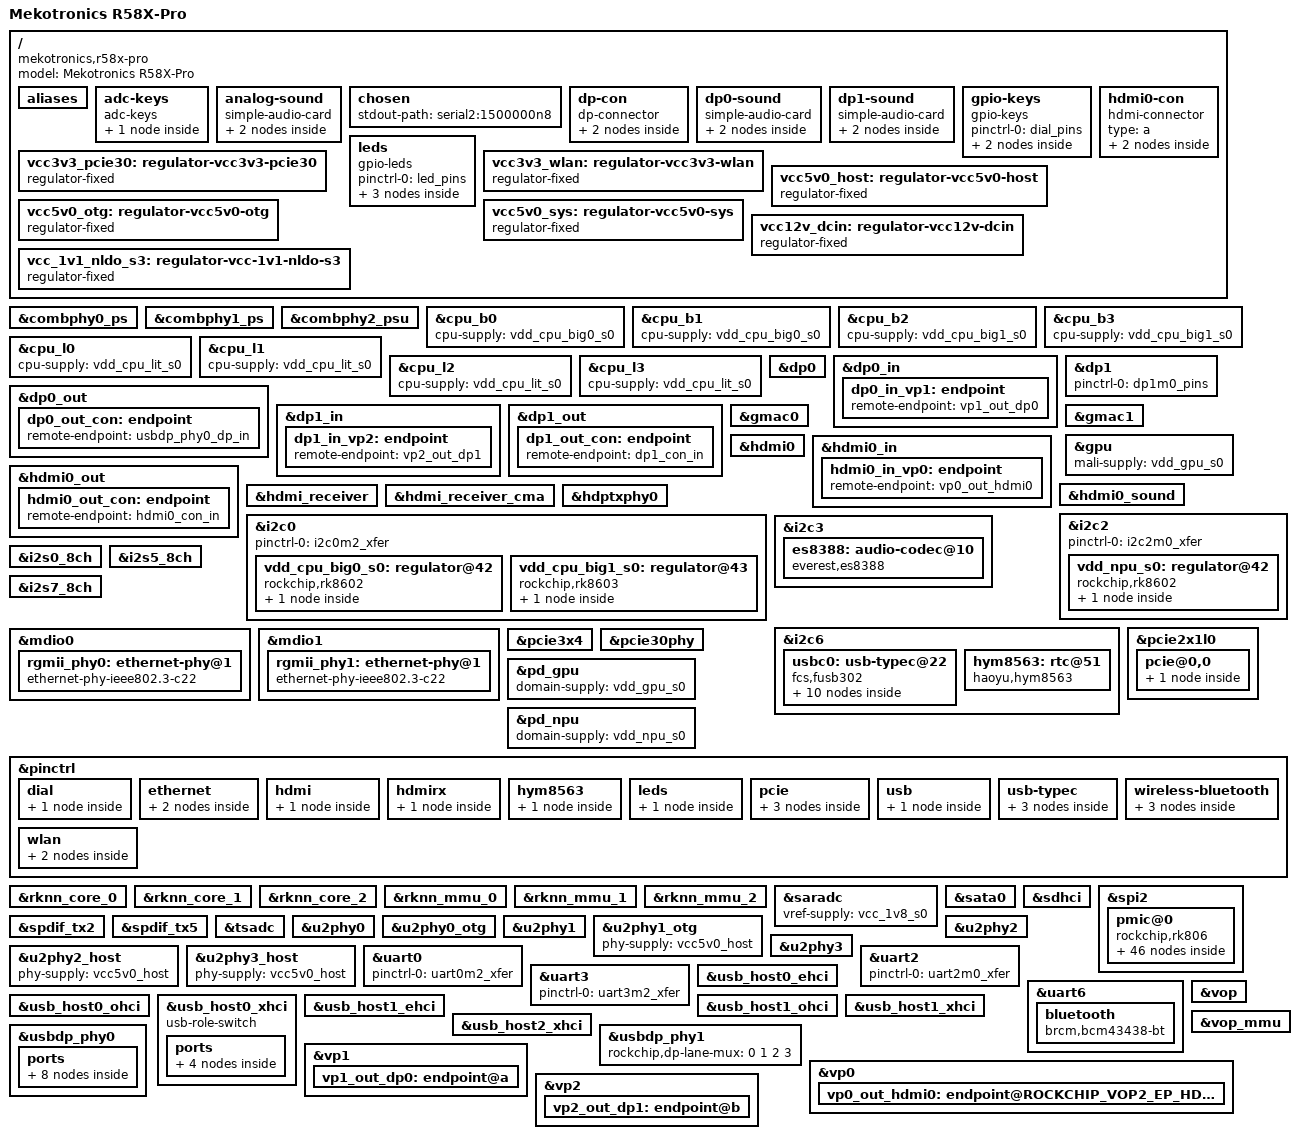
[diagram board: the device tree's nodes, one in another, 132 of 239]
// SPDX-License-Identifier: (GPL-2.0+ OR MIT)
/*
 * Copyright (c) 2026 Ricardo Pardini <ricardo@pardini.net>
 */

/dts-v1/;

#include <dt-bindings/gpio/gpio.h>
#include <dt-bindings/input/input.h>
#include <dt-bindings/leds/common.h>
#include <dt-bindings/pinctrl/rockchip.h>
#include <dt-bindings/soc/rockchip,vop2.h>
#include <dt-bindings/usb/pd.h>
#include "rk3588.dtsi"

/ {
	model = "Mekotronics R58X-Pro";
	compatible = "mekotronics,r58x-pro", "rockchip,rk3588";

	aliases {
		ethernet0 = &gmac0;
		ethernet1 = &gmac1;
		mmc0 = &sdhci;
	};

	adc-keys {
		compatible = "adc-keys";
		io-channels = <&saradc 1>;
		io-channel-names = "buttons";
		keyup-threshold-microvolt = <1800000>;
		poll-interval = <100>;

		button-recovery {
			label = "Recovery";
			linux,code = <KEY_VENDOR>;
			press-threshold-microvolt = <17000>;
		};
	};

	analog-sound {
		compatible = "simple-audio-card";
		simple-audio-card,name = "rockchip-es8388";
		simple-audio-card,bitclock-master = <&daicpu>;
		simple-audio-card,format = "i2s";
		simple-audio-card,frame-master = <&daicpu>;
		simple-audio-card,mclk-fs = <256>;
		simple-audio-card,routing =
			"Headphones", "LOUT1",
			"Headphones", "ROUT1",
			"LINPUT2", "Microphone Jack";
		simple-audio-card,widgets =
			"Microphone", "Microphone Jack",
			"Headphone", "Headphones";

		simple-audio-card,codec {
			sound-dai = <&es8388>;
			system-clock-frequency = <12288000>;
		};

		daicpu: simple-audio-card,cpu {
			sound-dai = <&i2s0_8ch>;
		};
	};

	chosen {
		stdout-path = "serial2:1500000n8";
	};

	dp-con {
		compatible = "dp-connector";
		label = "DP";
		type = "full-size";

		port {
			dp1_con_in: endpoint {
				remote-endpoint = <&dp1_out_con>;
			};
		};
	};

	dp0-sound {
		compatible = "simple-audio-card";
		simple-audio-card,mclk-fs = <512>;
		simple-audio-card,name = "RK3588 DP0";

		simple-audio-card,codec {
			sound-dai = <&dp0 1>;
		};

		simple-audio-card,cpu {
			sound-dai = <&spdif_tx2>;
		};
	};

	dp1-sound {
		compatible = "simple-audio-card";
		simple-audio-card,mclk-fs = <512>;
		simple-audio-card,name = "RK3588 DP1";

		simple-audio-card,codec {
			sound-dai = <&dp1 1>;
		};

		simple-audio-card,cpu {
			sound-dai = <&spdif_tx5>;
		};
	};

	gpio-keys {
		compatible = "gpio-keys";
		pinctrl-names = "default";
		pinctrl-0 = <&dial_pins>;

		key-volume-down {
			gpios = <&gpio3 RK_PC6 GPIO_ACTIVE_HIGH>;
			label = "Volume Down";
			linux,code = <KEY_VOLUMEDOWN>;
		};

		key-volume-up {
			gpios = <&gpio3 RK_PD0 GPIO_ACTIVE_HIGH>;
			label = "Volume Up";
			linux,code = <KEY_VOLUMEUP>;
		};
	};

	hdmi0-con {
		compatible = "hdmi-connector";
		type = "a";

		port {
			hdmi0_con_in: endpoint {
				remote-endpoint = <&hdmi0_out_con>;
			};
		};
	};

	leds {
		compatible = "gpio-leds";
		pinctrl-names = "default";
		pinctrl-0 = <&led_pins>;

		led-0 {
			color = <LED_COLOR_ID_GREEN>;
			function = LED_FUNCTION_LAN;
			gpios = <&gpio3 RK_PC0 GPIO_ACTIVE_HIGH>;
		};

		led-1 {
			color = <LED_COLOR_ID_BLUE>;
			default-state = "on";
			function = LED_FUNCTION_POWER;
			gpios = <&gpio3 RK_PB7 GPIO_ACTIVE_HIGH>;
		};

		led-2 {
			color = <LED_COLOR_ID_GREEN>;
			function = LED_FUNCTION_WLAN;
			gpios = <&gpio3 RK_PC5 GPIO_ACTIVE_HIGH>;
		};
	};

	vcc3v3_pcie30: regulator-vcc3v3-pcie30 {
		compatible = "regulator-fixed";
		enable-active-high;
		gpios = <&gpio1 RK_PC4 GPIO_ACTIVE_HIGH>;
		pinctrl-names = "default";
		pinctrl-0 = <&pcie30x4_pwren>;
		regulator-name = "vcc3v3_pcie30";
		regulator-min-microvolt = <3300000>;
		regulator-max-microvolt = <3300000>;
		startup-delay-us = <10000>;
		vin-supply = <&vcc12v_dcin>;
	};

	vcc3v3_wlan: regulator-vcc3v3-wlan {
		compatible = "regulator-fixed";
		enable-active-high;
		gpios = <&gpio1 RK_PB1 GPIO_ACTIVE_HIGH>;
		pinctrl-names = "default";
		pinctrl-0 = <&wifi_pwren>;
		regulator-name = "vcc3v3_wlan";
		regulator-min-microvolt = <3300000>;
		regulator-max-microvolt = <3300000>;
		vin-supply = <&vcc12v_dcin>;
	};

	vcc5v0_host: regulator-vcc5v0-host {
		compatible = "regulator-fixed";
		enable-active-high;
		gpio = <&gpio4 RK_PB0 GPIO_ACTIVE_HIGH>;
		pinctrl-names = "default";
		pinctrl-0 = <&vcc5v0_host_en>;
		regulator-name = "vcc5v0_host";
		regulator-min-microvolt = <5000000>;
		regulator-max-microvolt = <5000000>;
		vin-supply = <&vcc5v0_sys>;
	};

	vcc5v0_otg: regulator-vcc5v0-otg {
		compatible = "regulator-fixed";
		enable-active-high;
		gpio = <&gpio4 RK_PA7 GPIO_ACTIVE_HIGH>;
		pinctrl-names = "default";
		pinctrl-0 = <&vcc5v0_otg_en>;
		regulator-name = "vcc5v0_otg";
		regulator-min-microvolt = <5000000>;
		regulator-max-microvolt = <5000000>;
		vin-supply = <&vcc5v0_sys>;
	};

	vcc5v0_sys: regulator-vcc5v0-sys {
		compatible = "regulator-fixed";
		regulator-name = "vcc5v0_sys";
		regulator-always-on;
		regulator-boot-on;
		regulator-min-microvolt = <5000000>;
		regulator-max-microvolt = <5000000>;
		vin-supply = <&vcc12v_dcin>;
	};

	vcc12v_dcin: regulator-vcc12v-dcin {
		compatible = "regulator-fixed";
		regulator-name = "vcc12v_dcin";
		regulator-always-on;
		regulator-boot-on;
		regulator-min-microvolt = <12000000>;
		regulator-max-microvolt = <12000000>;
	};

	vcc_1v1_nldo_s3: regulator-vcc-1v1-nldo-s3 {
		compatible = "regulator-fixed";
		regulator-name = "vcc_1v1_nldo_s3";
		regulator-always-on;
		regulator-boot-on;
		regulator-min-microvolt = <1100000>;
		regulator-max-microvolt = <1100000>;
		vin-supply = <&vcc5v0_sys>;
	};
};

&combphy0_ps {
	status = "okay";
};

&combphy1_ps {
	status = "okay";
};

&combphy2_psu {
	status = "okay";
};

&cpu_b0 {
	cpu-supply = <&vdd_cpu_big0_s0>;
};

&cpu_b1 {
	cpu-supply = <&vdd_cpu_big0_s0>;
};

&cpu_b2 {
	cpu-supply = <&vdd_cpu_big1_s0>;
};

&cpu_b3 {
	cpu-supply = <&vdd_cpu_big1_s0>;
};

&cpu_l0 {
	cpu-supply = <&vdd_cpu_lit_s0>;
};

&cpu_l1 {
	cpu-supply = <&vdd_cpu_lit_s0>;
};

&cpu_l2 {
	cpu-supply = <&vdd_cpu_lit_s0>;
};

&cpu_l3 {
	cpu-supply = <&vdd_cpu_lit_s0>;
};

&dp0 {
	#sound-dai-cells = <1>;
	status = "okay";
};

&dp0_in {
	dp0_in_vp1: endpoint {
		remote-endpoint = <&vp1_out_dp0>;
	};
};

&dp0_out {
	dp0_out_con: endpoint {
		remote-endpoint = <&usbdp_phy0_dp_in>;
	};
};

&dp1 {
	pinctrl-names = "default";
	pinctrl-0 = <&dp1m0_pins>;
	#sound-dai-cells = <1>;
	status = "okay";
};

&dp1_in {
	dp1_in_vp2: endpoint {
		remote-endpoint = <&vp2_out_dp1>;
	};
};

&dp1_out {
	dp1_out_con: endpoint {
		remote-endpoint = <&dp1_con_in>;
	};
};

&gmac0 {
	clock_in_out = "output";
	phy-handle = <&rgmii_phy0>;
	/* RX delay is added by the PHY, TX delay by the GMAC */
	phy-mode = "rgmii-rxid";
	pinctrl-names = "default";
	pinctrl-0 = <&gmac0_miim
		     &gmac0_tx_bus2
		     &gmac0_rx_bus2
		     &gmac0_rgmii_clk
		     &gmac0_rgmii_bus>;
	tx_delay = <0x44>;
	status = "okay";
};

&gmac1 {
	clock_in_out = "output";
	phy-handle = <&rgmii_phy1>;
	phy-mode = "rgmii-id";
	pinctrl-names = "default";
	pinctrl-0 = <&gmac1_miim
		     &gmac1_tx_bus2
		     &gmac1_rx_bus2
		     &gmac1_rgmii_clk
		     &gmac1_rgmii_bus>;
	status = "okay";
};

&gpu {
	mali-supply = <&vdd_gpu_s0>;
	status = "okay";
};

&hdmi0 {
	frl-enable-gpios = <&gpio4 RK_PB1 GPIO_ACTIVE_LOW>;
	pinctrl-names = "default";
	pinctrl-0 = <&hdmim0_tx0_cec &hdmim0_tx0_hpd
		     &hdmim0_tx0_scl &hdmim0_tx0_sda &hdmi0_tx_on_h>;
	status = "okay";
};

&hdmi0_in {
	hdmi0_in_vp0: endpoint {
		remote-endpoint = <&vp0_out_hdmi0>;
	};
};

&hdmi0_out {
	hdmi0_out_con: endpoint {
		remote-endpoint = <&hdmi0_con_in>;
	};
};

&hdmi0_sound {
	status = "okay";
};

&hdmi_receiver {
	hpd-gpios = <&gpio1 RK_PD5 GPIO_ACTIVE_LOW>;
	pinctrl-names = "default";
	pinctrl-0 = <&hdmim1_rx_cec &hdmim1_rx_hpdin &hdmim1_rx_scl &hdmim1_rx_sda &hdmirx_5v_det>;
	status = "okay";
};

&hdmi_receiver_cma {
	status = "okay";
};

&hdptxphy0 {
	status = "okay";
};

&i2c0 {
	pinctrl-names = "default";
	pinctrl-0 = <&i2c0m2_xfer>;
	status = "okay";

	vdd_cpu_big0_s0: regulator@42 {
		compatible = "rockchip,rk8602";
		reg = <0x42>;
		fcs,suspend-voltage-selector = <1>;
		regulator-name = "vdd_cpu_big0_s0";
		regulator-always-on;
		regulator-boot-on;
		regulator-min-microvolt = <550000>;
		regulator-max-microvolt = <1050000>;
		regulator-ramp-delay = <2300>;
		vin-supply = <&vcc5v0_sys>;

		regulator-state-mem {
			regulator-off-in-suspend;
		};
	};

	vdd_cpu_big1_s0: regulator@43 {
		compatible = "rockchip,rk8603", "rockchip,rk8602";
		reg = <0x43>;
		fcs,suspend-voltage-selector = <1>;
		regulator-name = "vdd_cpu_big1_s0";
		regulator-always-on;
		regulator-boot-on;
		regulator-min-microvolt = <550000>;
		regulator-max-microvolt = <1050000>;
		regulator-ramp-delay = <2300>;
		vin-supply = <&vcc5v0_sys>;

		regulator-state-mem {
			regulator-off-in-suspend;
		};
	};
};

&i2c2 {
	pinctrl-names = "default";
	pinctrl-0 = <&i2c2m0_xfer>;
	status = "okay";

	vdd_npu_s0: regulator@42 {
		compatible = "rockchip,rk8602";
		reg = <0x42>;
		fcs,suspend-voltage-selector = <1>;
		regulator-name = "vdd_npu_s0";
		regulator-boot-on;
		regulator-min-microvolt = <550000>;
		regulator-max-microvolt = <950000>;
		regulator-ramp-delay = <2300>;
		vin-supply = <&vcc5v0_sys>;

		regulator-state-mem {
			regulator-off-in-suspend;
		};
	};
};

&i2c3 {
	status = "okay";

	es8388: audio-codec@10 {
		compatible = "everest,es8388", "everest,es8328";
		reg = <0x10>;
		assigned-clocks = <&cru I2S0_8CH_MCLKOUT>;
		assigned-clock-rates = <12288000>;
		clocks = <&cru I2S0_8CH_MCLKOUT_TO_IO>;
		pinctrl-names = "default";
		pinctrl-0 = <&i2s0_mclk>;
		AVDD-supply = <&avcc_1v8_s0>;
		DVDD-supply = <&avcc_1v8_s0>;
		HPVDD-supply = <&vcc_3v3_s0>;
		PVDD-supply = <&vcc_3v3_s0>;
		#sound-dai-cells = <0>;
	};
};

&i2c6 {
	status = "okay";

	usbc0: usb-typec@22 {
		compatible = "fcs,fusb302";
		reg = <0x22>;
		interrupt-parent = <&gpio3>;
		interrupts = <RK_PC7 IRQ_TYPE_LEVEL_LOW>;
		pinctrl-names = "default";
		pinctrl-0 = <&usbc0_int>;
		vbus-supply = <&vcc5v0_otg>;

		connector {
			compatible = "usb-c-connector";
			data-role = "dual";
			label = "USB-C";
			power-role = "source";
			source-pdos = <PDO_FIXED(5000, 1500, PDO_FIXED_USB_COMM)>;

			altmodes {
				displayport {
					svid = /bits/ 16 <0xff01>;
					vdo = <0xffffffff>;
				};
			};

			ports {
				#address-cells = <1>;
				#size-cells = <0>;

				port@0 {
					reg = <0>;

					usbc0_hs: endpoint {
						remote-endpoint = <&usb_host0_xhci_hs>;
					};
				};

				port@1 {
					reg = <1>;

					usbc0_ss: endpoint {
						remote-endpoint = <&usbdp_phy0_ss_out>;
					};
				};

				port@2 {
					reg = <2>;

					usbc0_sbu: endpoint {
						remote-endpoint = <&usbdp_phy0_aux_out>;
					};
				};
			};
		};
	};

	hym8563: rtc@51 {
		compatible = "haoyu,hym8563";
		reg = <0x51>;
		#clock-cells = <0>;
		clock-output-names = "hym8563";
		interrupt-parent = <&gpio0>;
		interrupts = <RK_PB2 IRQ_TYPE_LEVEL_LOW>;
		pinctrl-names = "default";
		pinctrl-0 = <&hym8563_int>;
		wakeup-source;
	};
};

&i2s0_8ch {
	pinctrl-names = "default";
	pinctrl-0 = <&i2s0_lrck
		     &i2s0_sclk
		     &i2s0_sdi0
		     &i2s0_sdo0>;
	status = "okay";
};

&i2s5_8ch {
	status = "okay";
};

&i2s7_8ch {
	status = "okay";
};

&mdio0 {
	rgmii_phy0: ethernet-phy@1 {
		compatible = "ethernet-phy-ieee802.3-c22";
		reg = <0x1>;
		pinctrl-names = "default";
		pinctrl-0 = <&gmac0_phy_rst>;
		reset-assert-us = <20000>;
		reset-deassert-us = <100000>;
		reset-gpios = <&gpio4 RK_PB3 GPIO_ACTIVE_LOW>;
	};
};

&mdio1 {
	rgmii_phy1: ethernet-phy@1 {
		compatible = "ethernet-phy-ieee802.3-c22";
		reg = <0x1>;
		pinctrl-names = "default";
		pinctrl-0 = <&gmac1_phy_rst>;
		reset-assert-us = <20000>;
		reset-deassert-us = <100000>;
		reset-gpios = <&gpio4 RK_PA2 GPIO_ACTIVE_LOW>;
	};
};

&pcie2x1l0 {
	pinctrl-names = "default";
	pinctrl-0 = <&pcie2_0_rst>, <&wifi_host_wake_irq>;
	reset-gpios = <&gpio1 RK_PB4 GPIO_ACTIVE_HIGH>;
	vpcie3v3-supply = <&vcc3v3_wlan>;
	status = "okay";

	pcie@0,0 {
		device_type = "pci";
		reg = <0x200000 0 0 0 0>;
		ranges;
		#address-cells = <3>;
		#size-cells = <2>;
		bus-range = <0x20 0x2f>;

		wifi: wifi@0,0 {
			compatible = "pci14e4,449d";
			reg = <0x210000 0 0 0 0>;
			clocks = <&hym8563>;
			clock-names = "lpo";
		};
	};
};

&pcie3x4 {
	pinctrl-names = "default";
	pinctrl-0 = <&pcie3x4_rst>;
	reset-gpios = <&gpio4 RK_PB6 GPIO_ACTIVE_HIGH>;
	vpcie3v3-supply = <&vcc3v3_pcie30>;
	status = "okay";
};

&pcie30phy {
	status = "okay";
};

&pd_gpu {
	domain-supply = <&vdd_gpu_s0>;
};

&pd_npu {
	domain-supply = <&vdd_npu_s0>;
};

&pinctrl {
	dial {
		dial_pins: dial-pins {
			rockchip,pins = <3 RK_PC6 RK_FUNC_GPIO &pcfg_pull_up>,
					<3 RK_PD0 RK_FUNC_GPIO &pcfg_pull_up>;
		};
	};

	ethernet {
		gmac0_phy_rst: gmac0-phy-rst {
			rockchip,pins = <4 RK_PB3 RK_FUNC_GPIO &pcfg_pull_none>;
		};

		gmac1_phy_rst: gmac1-phy-rst {
			rockchip,pins = <4 RK_PA2 RK_FUNC_GPIO &pcfg_pull_none>;
		};
	};

	hdmi {
		hdmi0_tx_on_h: hdmi0-tx-on-h {
			rockchip,pins = <4 RK_PB1 RK_FUNC_GPIO &pcfg_pull_none>;
		};
	};

	hdmirx {
		hdmirx_5v_det: hdmirx-5v-det {
			rockchip,pins = <1 RK_PD5 RK_FUNC_GPIO &pcfg_pull_up>;
		};
	};

	hym8563 {
		hym8563_int: hym8563-int {
			rockchip,pins = <0 RK_PB2 RK_FUNC_GPIO &pcfg_pull_up>;
		};
	};

	leds {
		led_pins: led-pins {
			rockchip,pins = <3 RK_PB7 RK_FUNC_GPIO &pcfg_pull_none>,
					<3 RK_PC0 RK_FUNC_GPIO &pcfg_pull_none>,
					<3 RK_PC5 RK_FUNC_GPIO &pcfg_pull_none>;
		};
	};

	pcie {
		pcie2_0_rst: pcie2-0-rst {
			rockchip,pins = <1 RK_PB4 RK_FUNC_GPIO &pcfg_pull_none>;
		};

		pcie3x4_rst: pcie3x4-rst {
			rockchip,pins = <4 RK_PB6 RK_FUNC_GPIO &pcfg_pull_none>;
		};

		pcie30x4_pwren: pcie30x4-pwren {
			rockchip,pins = <1 RK_PC4 RK_FUNC_GPIO &pcfg_pull_up>;
		};
	};

	usb {
		vcc5v0_host_en: vcc5v0-host-en {
			rockchip,pins = <4 RK_PB0 RK_FUNC_GPIO &pcfg_pull_none>;
		};
	};

	usb-typec {
		usbc0_int: usbc0-int {
			rockchip,pins = <3 RK_PC7 RK_FUNC_GPIO &pcfg_pull_up>;
		};

		usbc0_sbu_dc: usbc0-sbu-dc {
			rockchip,pins = <0 RK_PC6 RK_FUNC_GPIO &pcfg_pull_none>,
					<0 RK_PD3 RK_FUNC_GPIO &pcfg_pull_none>;
		};

		vcc5v0_otg_en: vcc5v0-otg-en {
			rockchip,pins = <4 RK_PA7 RK_FUNC_GPIO &pcfg_pull_none>;
		};
	};

	wireless-bluetooth {
		bt_reset_pin: bt-reset-pin {
			rockchip,pins = <1 RK_PB2 RK_FUNC_GPIO &pcfg_pull_none>;
		};

		bt_wake_host_irq: bt-wake-host-irq {
			rockchip,pins = <1 RK_PB0 RK_FUNC_GPIO &pcfg_pull_down>;
		};

		bt_wake_pin: bt-wake-pin {
			rockchip,pins = <1 RK_PA4 RK_FUNC_GPIO &pcfg_pull_down>;
		};
	};

	wlan {
		wifi_host_wake_irq: wifi-host-wake-irq {
			rockchip,pins = <1 RK_PA7 RK_FUNC_GPIO &pcfg_pull_down>;
		};

		wifi_pwren: wifi-pwren {
			rockchip,pins = <1 RK_PB1 RK_FUNC_GPIO &pcfg_pull_up>;
		};
	};
};

&rknn_core_0 {
	npu-supply = <&vdd_npu_s0>;
	sram-supply = <&vdd_npu_s0>;
	status = "okay";
};

&rknn_core_1 {
	npu-supply = <&vdd_npu_s0>;
	sram-supply = <&vdd_npu_s0>;
	status = "okay";
};

&rknn_core_2 {
	npu-supply = <&vdd_npu_s0>;
	sram-supply = <&vdd_npu_s0>;
	status = "okay";
};

&rknn_mmu_0 {
	status = "okay";
};

&rknn_mmu_1 {
	status = "okay";
};

&rknn_mmu_2 {
	status = "okay";
};

&saradc {
	vref-supply = <&vcc_1v8_s0>;
	status = "okay";
};

&sata0 {
	status = "okay";
};

&sdhci {
	bus-width = <8>;
	mmc-hs200-1_8v;
	no-sd;
	no-sdio;
	non-removable;
	status = "okay";
};

&spi2 {
	assigned-clocks = <&cru CLK_SPI2>;
	assigned-clock-rates = <200000000>;
	num-cs = <1>;
	pinctrl-names = "default";
	pinctrl-0 = <&spi2m2_cs0 &spi2m2_pins>;
	status = "okay";

	pmic@0 {
		compatible = "rockchip,rk806";
		reg = <0x0>;
		interrupt-parent = <&gpio0>;
		interrupts = <7 IRQ_TYPE_LEVEL_LOW>;
		pinctrl-names = "default";
		pinctrl-0 = <&pmic_pins>, <&rk806_dvs1_null>,
			    <&rk806_dvs2_null>, <&rk806_dvs3_null>;
		spi-max-frequency = <1000000>;
		system-power-controller;

		vcc1-supply = <&vcc5v0_sys>;
		vcc2-supply = <&vcc5v0_sys>;
		vcc3-supply = <&vcc5v0_sys>;
		vcc4-supply = <&vcc5v0_sys>;
		vcc5-supply = <&vcc5v0_sys>;
		vcc6-supply = <&vcc5v0_sys>;
		vcc7-supply = <&vcc5v0_sys>;
		vcc8-supply = <&vcc5v0_sys>;
		vcc9-supply = <&vcc5v0_sys>;
		vcc10-supply = <&vcc5v0_sys>;
		vcc11-supply = <&vcc_2v0_pldo_s3>;
		vcc12-supply = <&vcc5v0_sys>;
		vcc13-supply = <&vcc_1v1_nldo_s3>;
		vcc14-supply = <&vcc_1v1_nldo_s3>;
		vcca-supply = <&vcc5v0_sys>;

		gpio-controller;
		#gpio-cells = <2>;

		rk806_dvs1_null: dvs1-null-pins {
			pins = "gpio_pwrctrl1";
			function = "pin_fun0";
		};

		rk806_dvs2_null: dvs2-null-pins {
			pins = "gpio_pwrctrl2";
			function = "pin_fun0";
		};

		rk806_dvs3_null: dvs3-null-pins {
			pins = "gpio_pwrctrl3";
			function = "pin_fun0";
		};

		regulators {
			vdd_gpu_s0: vdd_gpu_mem_s0: dcdc-reg1 {
				regulator-boot-on;
				regulator-min-microvolt = <550000>;
				regulator-max-microvolt = <950000>;
				regulator-ramp-delay = <12500>;
				regulator-name = "vdd_gpu_s0";
				regulator-enable-ramp-delay = <400>;

				regulator-state-mem {
					regulator-off-in-suspend;
				};
			};

			vdd_cpu_lit_s0: vdd_cpu_lit_mem_s0: dcdc-reg2 {
				regulator-always-on;
				regulator-boot-on;
				regulator-min-microvolt = <550000>;
				regulator-max-microvolt = <950000>;
				regulator-ramp-delay = <12500>;
				regulator-name = "vdd_cpu_lit_s0";

				regulator-state-mem {
					regulator-off-in-suspend;
				};
			};

			vdd_log_s0: dcdc-reg3 {
				regulator-always-on;
				regulator-boot-on;
				regulator-min-microvolt = <675000>;
				regulator-max-microvolt = <800000>;
				regulator-ramp-delay = <12500>;
				regulator-name = "vdd_log_s0";

				regulator-state-mem {
					regulator-off-in-suspend;
					regulator-suspend-microvolt = <750000>;
				};
			};

			vdd_vdenc_s0: vdd_vdenc_mem_s0: dcdc-reg4 {
				regulator-always-on;
				regulator-boot-on;
				regulator-min-microvolt = <550000>;
				regulator-max-microvolt = <950000>;
				regulator-ramp-delay = <12500>;
				regulator-name = "vdd_vdenc_s0";

				regulator-state-mem {
					regulator-off-in-suspend;
				};
			};

			vdd_ddr_s0: dcdc-reg5 {
				regulator-always-on;
				regulator-boot-on;
				regulator-min-microvolt = <675000>;
				regulator-max-microvolt = <900000>;
				regulator-ramp-delay = <12500>;
				regulator-name = "vdd_ddr_s0";

				regulator-state-mem {
					regulator-off-in-suspend;
					regulator-suspend-microvolt = <850000>;
				};
			};

			vdd2_ddr_s3: dcdc-reg6 {
				regulator-always-on;
				regulator-boot-on;
				regulator-name = "vdd2_ddr_s3";

				regulator-state-mem {
					regulator-on-in-suspend;
				};
			};

			vcc_2v0_pldo_s3: dcdc-reg7 {
				regulator-always-on;
				regulator-boot-on;
				regulator-min-microvolt = <2000000>;
				regulator-max-microvolt = <2000000>;
				regulator-ramp-delay = <12500>;
				regulator-name = "vdd_2v0_pldo_s3";

				regulator-state-mem {
					regulator-on-in-suspend;
					regulator-suspend-microvolt = <2000000>;
				};
			};

			vcc_3v3_s3: dcdc-reg8 {
				regulator-always-on;
				regulator-boot-on;
				regulator-min-microvolt = <3300000>;
				regulator-max-microvolt = <3300000>;
				regulator-name = "vcc_3v3_s3";

				regulator-state-mem {
					regulator-on-in-suspend;
					regulator-suspend-microvolt = <3300000>;
				};
			};

			vddq_ddr_s0: dcdc-reg9 {
				regulator-always-on;
				regulator-boot-on;
				regulator-name = "vddq_ddr_s0";

				regulator-state-mem {
					regulator-off-in-suspend;
				};
			};

			vcc_1v8_s3: dcdc-reg10 {
				regulator-always-on;
				regulator-boot-on;
				regulator-min-microvolt = <1800000>;
				regulator-max-microvolt = <1800000>;
				regulator-name = "vcc_1v8_s3";

				regulator-state-mem {
					regulator-on-in-suspend;
					regulator-suspend-microvolt = <1800000>;
				};
			};

			avcc_1v8_s0: pldo-reg1 {
				regulator-always-on;
				regulator-boot-on;
				regulator-min-microvolt = <1800000>;
				regulator-max-microvolt = <1800000>;
				regulator-name = "avcc_1v8_s0";

				regulator-state-mem {
					regulator-off-in-suspend;
				};
			};

			vcc_1v8_s0: pldo-reg2 {
				regulator-always-on;
				regulator-boot-on;
				regulator-min-microvolt = <1800000>;
				regulator-max-microvolt = <1800000>;
				regulator-name = "vcc_1v8_s0";

				regulator-state-mem {
					regulator-off-in-suspend;
					regulator-suspend-microvolt = <1800000>;
				};
			};

			avdd_1v2_s0: pldo-reg3 {
				regulator-always-on;
				regulator-boot-on;
				regulator-min-microvolt = <1200000>;
				regulator-max-microvolt = <1200000>;
				regulator-name = "avdd_1v2_s0";

				regulator-state-mem {
					regulator-off-in-suspend;
				};
			};

			vcc_3v3_s0: pldo-reg4 {
				regulator-always-on;
				regulator-boot-on;
				regulator-min-microvolt = <3300000>;
				regulator-max-microvolt = <3300000>;
				regulator-ramp-delay = <12500>;
				regulator-name = "vcc_3v3_s0";

				regulator-state-mem {
					regulator-off-in-suspend;
				};
			};

			vccio_sd_s0: pldo-reg5 {
				regulator-always-on;
				regulator-boot-on;
				regulator-min-microvolt = <1800000>;
				regulator-max-microvolt = <3300000>;
				regulator-ramp-delay = <12500>;
				regulator-name = "vccio_sd_s0";

				regulator-state-mem {
					regulator-off-in-suspend;
				};
			};

			pldo6_s3: pldo-reg6 {
				regulator-always-on;
				regulator-boot-on;
				regulator-min-microvolt = <1800000>;
				regulator-max-microvolt = <1800000>;
				regulator-name = "pldo6_s3";

				regulator-state-mem {
					regulator-on-in-suspend;
					regulator-suspend-microvolt = <1800000>;
				};
			};

			vdd_0v75_s3: nldo-reg1 {
				regulator-always-on;
				regulator-boot-on;
				regulator-min-microvolt = <750000>;
				regulator-max-microvolt = <750000>;
				regulator-name = "vdd_0v75_s3";

				regulator-state-mem {
					regulator-on-in-suspend;
					regulator-suspend-microvolt = <750000>;
				};
			};

			vdd_ddr_pll_s0: nldo-reg2 {
				regulator-always-on;
				regulator-boot-on;
				regulator-min-microvolt = <850000>;
				regulator-max-microvolt = <850000>;
				regulator-name = "vdd_ddr_pll_s0";

				regulator-state-mem {
					regulator-off-in-suspend;
					regulator-suspend-microvolt = <850000>;
				};
			};

			avdd_0v75_s0: nldo-reg3 {
				regulator-always-on;
				regulator-boot-on;
				regulator-min-microvolt = <750000>;
				regulator-max-microvolt = <750000>;
				regulator-name = "avdd_0v75_s0";

				regulator-state-mem {
					regulator-off-in-suspend;
				};
			};

			vdd_0v85_s0: nldo-reg4 {
				regulator-always-on;
				regulator-boot-on;
				regulator-min-microvolt = <850000>;
				regulator-max-microvolt = <850000>;
				regulator-name = "vdd_0v85_s0";

				regulator-state-mem {
					regulator-off-in-suspend;
				};
			};

			vdd_0v75_s0: nldo-reg5 {
				regulator-always-on;
				regulator-boot-on;
				regulator-min-microvolt = <750000>;
				regulator-max-microvolt = <750000>;
				regulator-name = "vdd_0v75_s0";

				regulator-state-mem {
					regulator-off-in-suspend;
				};
			};
		};
	};
};

&spdif_tx2 {
	status = "okay";
};

&spdif_tx5 {
	status = "okay";
};

&tsadc {
	status = "okay";
};

&u2phy0 {
	status = "okay";
};

&u2phy0_otg {
	status = "okay";
};

&u2phy1 {
	status = "okay";
};

&u2phy1_otg {
	phy-supply = <&vcc5v0_host>;
	status = "okay";
};

&u2phy2 {
	status = "okay";
};

&u2phy2_host {
	phy-supply = <&vcc5v0_host>;
	status = "okay";
};

&u2phy3 {
	status = "okay";
};

&u2phy3_host {
	phy-supply = <&vcc5v0_host>;
	status = "okay";
};

&uart0 {
	pinctrl-names = "default";
	pinctrl-0 = <&uart0m2_xfer>;
	status = "okay";
};

&uart2 {
	pinctrl-0 = <&uart2m0_xfer>;
	status = "okay";
};

&uart3 {
	pinctrl-names = "default";
	pinctrl-0 = <&uart3m2_xfer>;
	status = "okay";
};

&uart6 {
	pinctrl-names = "default";
	pinctrl-0 = <&uart6m1_xfer &uart6m1_ctsn &uart6m1_rtsn>;
	uart-has-rtscts;
	status = "okay";

	bluetooth {
		compatible = "brcm,bcm43438-bt";
		clocks = <&hym8563>;
		clock-names = "lpo";
		device-wakeup-gpios = <&gpio1 RK_PA4 GPIO_ACTIVE_HIGH>;
		interrupt-parent = <&gpio1>;
		interrupts = <RK_PB0 IRQ_TYPE_LEVEL_HIGH>;
		interrupt-names = "host-wakeup";
		max-speed = <1500000>;
		pinctrl-names = "default";
		pinctrl-0 = <&bt_wake_host_irq &bt_wake_pin &bt_reset_pin>;
		shutdown-gpios = <&gpio1 RK_PB2 GPIO_ACTIVE_HIGH>;
		vbat-supply = <&vcc_3v3_s3>;
		vddio-supply = <&vcc_1v8_s3>;
	};
};

&usb_host0_ehci {
	status = "okay";
};

&usb_host0_ohci {
	status = "okay";
};

&usb_host0_xhci {
	usb-role-switch;
	status = "okay";

	ports {
		#address-cells = <1>;
		#size-cells = <0>;

		port@0 {
			reg = <0>;

			usb_host0_xhci_hs: endpoint {
				remote-endpoint = <&usbc0_hs>;
			};
		};

		port@1 {
			reg = <1>;

			usb_host0_xhci_ss: endpoint {
				remote-endpoint = <&usbdp_phy0_ss_in>;
			};
		};
	};
};

&usb_host1_ehci {
	status = "okay";
};

&usb_host1_ohci {
	status = "okay";
};

/* USBDP PHY1 lanes are all used by the DP connector, so this is USB 2.0 only */
&usb_host1_xhci {
	dr_mode = "host";
	maximum-speed = "high-speed";
	status = "okay";
};

&usb_host2_xhci {
	status = "okay";
};

&usbdp_phy0 {
	mode-switch;
	orientation-switch;
	pinctrl-names = "default";
	pinctrl-0 = <&usbc0_sbu_dc>;
	sbu1-dc-gpios = <&gpio0 RK_PC6 GPIO_ACTIVE_HIGH>;
	sbu2-dc-gpios = <&gpio0 RK_PD3 GPIO_ACTIVE_HIGH>;
	status = "okay";

	ports {
		#address-cells = <1>;
		#size-cells = <0>;

		port@0 {
			reg = <0>;

			usbdp_phy0_ss_out: endpoint {
				remote-endpoint = <&usbc0_ss>;
			};
		};

		port@1 {
			reg = <1>;

			usbdp_phy0_ss_in: endpoint {
				remote-endpoint = <&usb_host0_xhci_ss>;
			};
		};

		port@2 {
			reg = <2>;

			usbdp_phy0_dp_in: endpoint {
				remote-endpoint = <&dp0_out_con>;
			};
		};

		port@3 {
			reg = <3>;

			usbdp_phy0_aux_out: endpoint {
				remote-endpoint = <&usbc0_sbu>;
			};
		};
	};
};

&usbdp_phy1 {
	rockchip,dp-lane-mux = <0 1 2 3>;
	status = "okay";
};

&vop {
	status = "okay";
};

&vop_mmu {
	status = "okay";
};

&vp0 {
	vp0_out_hdmi0: endpoint@ROCKCHIP_VOP2_EP_HDMI0 {
		reg = <ROCKCHIP_VOP2_EP_HDMI0>;
		remote-endpoint = <&hdmi0_in_vp0>;
	};
};

&vp1 {
	vp1_out_dp0: endpoint@a {
		reg = <ROCKCHIP_VOP2_EP_DP0>;
		remote-endpoint = <&dp0_in_vp1>;
	};
};

&vp2 {
	vp2_out_dp1: endpoint@b {
		reg = <ROCKCHIP_VOP2_EP_DP1>;
		remote-endpoint = <&dp1_in_vp2>;
	};
};
